# MIK32 register map
Vendor: Mikron; Series: MIK32; File version: 1.0
Registers are 32-bit, read-write, reset 0x0 unless marked. A register's access mark holds for its fields unless they carry their own. Offsets are from the block's base; [hi:lo] are bit positions; 'fields as' and 'values as' point back to an identical list.

## SPI_0 — Модуль обеспечивает взаимодействие с различными периферийными устройствами
Base 0x00083000
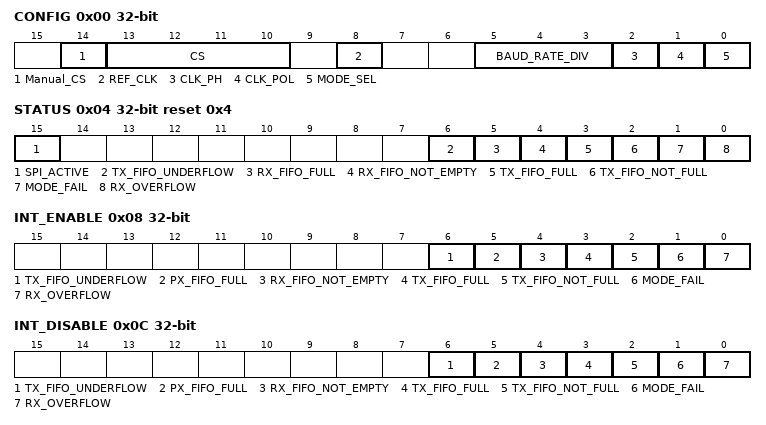
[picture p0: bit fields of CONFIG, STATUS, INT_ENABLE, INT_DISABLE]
0x00 CONFIG — Регистр конфигурации SPI
  [14] Manual_CS — Выбор режима управления сигналом выбора ведомого
    0=Automatic (Автоматический режим); 1=Manual (Ручной режим)
  [13:10] CS — Выбор ведомых устройств
    15=Not_selected (Ведомые устройства не выбраны); 1=CS1_1 (Выбрано устройство 1); 5=CS1_2 (Выбрано устройство 1); 9=CS1_3 (Выбрано устройство 1); 13=CS1_4 (Выбрано устройство 1); 3=CS2_1 (Выбрано устройство 2); 11=CS2_2 (Выбрано устройство 2); 7=Выбрано устройство 3; 0=Выбрано устройство 4; 2=Выбрано устройство 4; 4=Выбрано устройство 4; 8=Выбрано устройство 4; 10=Выбрано устройство 4; 12=Выбрано устройство 4; 6=Выбрано устройство 4; 14=Выбрано устройство 4
  [8] REF_CLK — Выбор опорной тактовой частоты
    0=Not_supported (Не поддерживается); 1=APB_P_CLK (Используется опорная частота SPI)
  [5:3] BAUD_RATE_DIV — Управляет скоростью передачи данных, задает коэффициент деления частоты spi_ref_clk
    0=Not_supported (Не поддерживается); 1=DIV4 (Деление на 4); 2=DIV8 (Деление на 8); 3=DIV16 (Деление на 16); 4=DIV32 (Деление на 32); 5=DIV64 (деление на 64); 6=DIV128 (деление на 128); 7=DIV256 (деление на 256)
  [2] CLK_PH — (CPHA)Выбор фазы тактового сигнала
    0=Тактовая частота SPI неактивна вне слова; 1=Тактовая частота SPI активна вне слова
  [1] CLK_POL — (CPOL)Выбор полярности тактового сигнала вне слова
    0=Тактовый сигнал вне слова удерживается на низком уровне; 1=Тактовый сигнал вне слова удерживается на высоком уровне
  [0] MODE_SEL — (MSTREN) Выбор режима
    0=Slave (SPI в режиме ведомого устройства); 1=Master (SPI в режиме ведущего устройства)
0x04 STATUS reset 0x4 — Регистр статуса. Примечание: биты регистра [6:0] устанавливаются в «1», если произошло событие вызывающее прерывание.
  [15] SPI_ACTIVE ro — Статус сеанса передачи
    0=Ready (Контроллер SPI в состоянии ожидания обмена); 1=Busy (Контроллер SPI в процессе обмена)
  [6] TX_FIFO_UNDERFLOW ro — (IXR_TXUF) Регистр TX FIFO опустошен. Устанавливается в режиме ведомого в случае, если к началу обмена в TX_FIFO нет данных
    0=Not_empty (Опустошение не детектируется); 1=Underflow (Определение опустошения)
  [5] RX_FIFO_FULL ro — (IXR_RXFULL) Регистр RX_FIFO заполнен
    0=Not_full (FIFO не заполнен); 1=Full (FIFO заполнен)
  [4] RX_FIFO_NOT_EMPTY ro — (IXR_RXNEMPTY) Регистр RX_FIFO не пустой
    0=Empty (FIFO пустой); 1=Not_empty (В FIFO есть хотя бы один байт)
  [3] TX_FIFO_FULL ro — (IXR_TXFULL) Регистр TX_FIFO заполнен
    0=Not_full (FIFO не заполнен); 1=Full (FIFO заполнен)
  [2] TX_FIFO_NOT_FULL ro — (IXR_TXOW) Регистр TX_FIFO не заполнен
    0=Less_than_the_threshold (Регистр заполнен до значение THRESHOLD или больше); 1=More_than_the_threshold (Регистр заполнен меньше чем THRESHOLD)
  [1] MODE_FAIL ro — (IXR_MODF) Напряжение на выводе n_ss_in не соответствую режиму работы SPI
    0=Ok (Корректная работа); 1=Fail (n_ss_in имеет низкий уровень в режиме ведомого устройства)
  [0] RX_OVERFLOW ro — (IXR_RXOVR) Прерывание при переполнении RX_FIFO, значение сбрасывается при чтении
    0=Ok (Нет переполнения); 1=Overflow (Переполнение RX_FIFO)
0x08 INT_ENABLE wo — Регистр разрешения прерываний
  [6] TX_FIFO_UNDERFLOW — (IXR_TXUF) Запись «1» устанавливает маску прерывания (разрешает прерывание) при опустошении TX_FIFO
  [5] PX_FIFO_FULL — (IXR_RXFULL) Запись «1» устанавливает маску прерывания (разрешает прерывание) при заполнении RX_FIFO
  [4] RX_FIFO_NOT_EMPTY — (IXR_RXNEMPTY) Запись «1» устанавливает маску прерывания (разрешает прерывание), когда RX_FIFO не пустой
  [3] TX_FIFO_FULL — (IXR_TXFULL) Запись «1» устанавливает маску прерывания (разрешает прерывание), когда TX_FIFO заполнен
  [2] TX_FIFO_NOT_FULL — (IXR_TXOW) Запись «1» устанавливает маску прерывания (разрешает прерывание) когда TX_FIFO не заполнен
  [1] MODE_FAIL — (IXR_MODF) Запись «1» устанавливает маску прерывания (разрешает прерывание) при нарушении режима
  [0] RX_OVERFLOW — (IXR_RXOVR) Запись «1» устанавливает маску прерывания (разрешает прерывание) при переполнении при приеме
0x0C INT_DISABLE wo — Регистр запрета прерываний
  [6] TX_FIFO_UNDERFLOW — (IXR_TXUF) Запись «1» сбрасывает маску прерывания (запрещает прерывание) при опустошении TX_FIFO
  [5] PX_FIFO_FULL — (IXR_RXFULL) Запись «1» сбрасывает маску прерывания (запрещает прерывание) при заполнении RX_FIFO
  [4] RX_FIFO_NOT_EMPTY — (IXR_RXNEMPTY) Запись «1» сбрасывает маску прерывания (запрещает прерывание), когда RX_FIFO не пустой
  [3] TX_FIFO_FULL — (IXR_TXFULL) Запись «1» сбрасывает маску прерывания (запрещает прерывание), когда TX_FIFO заполнен
  [2] TX_FIFO_NOT_FULL — (IXR_TXOW) Запись «1» сбрасывает маску прерывания (запрещает прерывание) когда TX_FIFO не заполнен
  [1] MODE_FAIL — (IXR_MODF) Запись «1» сбрасывает маску прерывания (запрещает прерывание) при нарушении режима
  [0] RX_OVERFLOW — (IXR_RXOVR) Запись «1» сбрасывает маску прерывания (запрещает прерывание) при переполнении при приеме
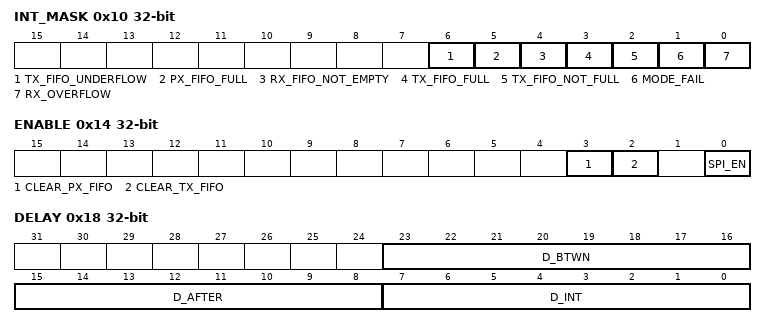
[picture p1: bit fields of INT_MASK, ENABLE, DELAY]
0x10 INT_MASK ro — Регистр текущих масок прерываний
  [all] fields
    0=Disable (Прерывание запрещено); 1=Enable (Прерывание разрешено)
  [6] TX_FIFO_UNDERFLOW — (IXR_TXUF) Текущее состояние маски прерывания при опустошении
  [5] PX_FIFO_FULL — (IXR_RXFULL) Текущее состояние маски прерывания при заполнении RX_FIFO
  [4] RX_FIFO_NOT_EMPTY — (IXR_RXNEMPTY) Текущее состояние маски прерывания, когда RX_FIFO не пустой
  [3] TX_FIFO_FULL — (IXR_TXFULL) Текущее состояние маски прерывания, когда TX_FIFO заполнен
  [2] TX_FIFO_NOT_FULL — (IXR_TXOW) Текущее состояние маски прерывания, когда TX_FIFO не заполнен
  [1] MODE_FAIL — (IXR_MODF) Текущее состояние маски прерывания при нарушении режима
  [0] RX_OVERFLOW — (IXR_RXOVR) Текущее состояние маски прерывания при переполнении при приеме
0x14 ENABLE — Регистр включения/выключения SPI
  [3] CLEAR_PX_FIFO wo — Запись 1 при SPI_EN = 0 очищает буфер RX_FIFO.
  [2] CLEAR_TX_FIFO wo — Запись 1 при SPI_EN = 0 очищает буфер TX_FIFO.
  [0] SPI_EN — (ENABLE) Включение/выключение модуля SPI
    0=Disable (Выключение модуля SPI); 1=Enable (Включение модуля SPI)
0x18 DELAY — Регистр задержек
  [23:16] D_BTWN — (BTWN) Задержка в периодах опорного тактового сигнала или внешнего тактового сигнала ext_clk между снятием сигнала выбора одного ведомого устройства и установкой сигнала выбора другого ведомого устройства
  [15:8] D_AFTER — (AFTER) Задержка в периодах опорного тактового сигнала или внешнего тактового сигнала ext_clk между последним битом текущего слова и первым битом следующего слова
  [7:0] D_INT — (INIT) Дополнительная задержка в периодах опорного тактового сигнала или внешнего тактового сигнала ext_clk между установкой сигнала n_ss_out в «0» и передачей первого бита
0x1C TXDATA wo — Регистр передаваемых данных
  [7:0] TX_FIFO_data — Данные для TX_FIFO
0x20 RXDATA ro — Регистр принимаемых данных
  [7:0] RX_FIFO_data — Данные из RX_FIFO.
0x24 SIC reset 0xFF — Регистр счетчика останова ведомого устройства
  [7:0] Slave_Idle_coun — Модуль SPI в режиме ведомого устройства начинает передачу только когда тактовый сигнал sclk_in (внешнего ведущего устройства) не изменяется в течение количества периодов опорного тактового сигнала SPI заданного в этом поле или когда модуль SPI не активен
0x28 TX_THR reset 0x1 — Регистр пороговых значений TX_FIFO
  [31:0] Threshold_of_TX_FIFO — Задает уровень, при котором TX_FIFO считается не заполненным и формируется прерывание
0x2C ID ro reset 0x1090100 — Идентификационный номер модуля
  [31:0] Threshold_of_TX_FIFO

## SPI_1 — Модуль обеспечивает взаимодействие с различными периферийными устройствами
Base 0x00083400
Registers as SPI_0; these are added or differ:
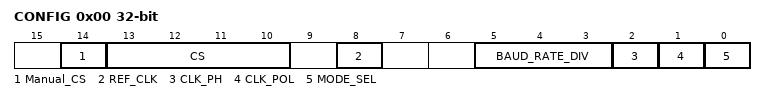
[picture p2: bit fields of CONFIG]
0x00 CONFIG — Регистр конфигурации SPI
  [14] Manual_CS — Выбор режима управления сигналом выбора ведомого
    0=Automatic (Автоматический режим); 1=Manual (Ручной режим)
  [13:10] CS — Выбор ведомых устройств
    15=Not_selected (Ведомые устройства не выбраны); 1=CS1_1 (Выбрано устройство 1); 5=CS1_2 (Выбрано устройство 1); 9=CS1_3 (Выбрано устройство 1); 13=CS1_4 (Выбрано устройство 1); 3=CS2_1 (Выбрано устройство 2); 11=CS2_2 (Выбрано устройство 2); 7=Выбрано устройство 3; 0=CS4_1 (Выбрано устройство 4); 4=CS4_2 (Выбрано устройство 4); 2=CS4_3 (Выбрано устройство 4); 8=CS4_4 (Выбрано устройство 4); 10=CS4_5 (Выбрано устройство 4); 12=CS4_6 (Выбрано устройство 4); 6=CS4_7 (Выбрано устройство 4); 14=CS4_8 (Выбрано устройство 4)
  [8] REF_CLK — Выбор опорной тактовой частоты
    0=Not_supported (Не поддерживается); 1=APB_P_CLK (Используется опорная частота SPI)
  [5:3] BAUD_RATE_DIV — Управляет скоростью передачи данных, задает коэффициент деления частоты spi_ref_clk
    values as SPI_0.CONFIG.BAUD_RATE_DIV
  [2] CLK_PH — (CPHA)Выбор фазы тактового сигнала
    0=Тактовая частота SPI неактивна вне слова; 1=Тактовая частота SPI активна вне слова
  [1] CLK_POL — (CPOL)Выбор полярности тактового сигнала вне слова
    0=Тактовый сигнал вне слова удерживается на низком уровне; 1=Тактовый сигнал вне слова удерживается на высоком уровне
  [0] MODE_SEL — (MSTREN) Выбор режима
    0=Slave (SPI в режиме ведомого устройства); 1=Master (SPI в режиме ведущего устройства)
